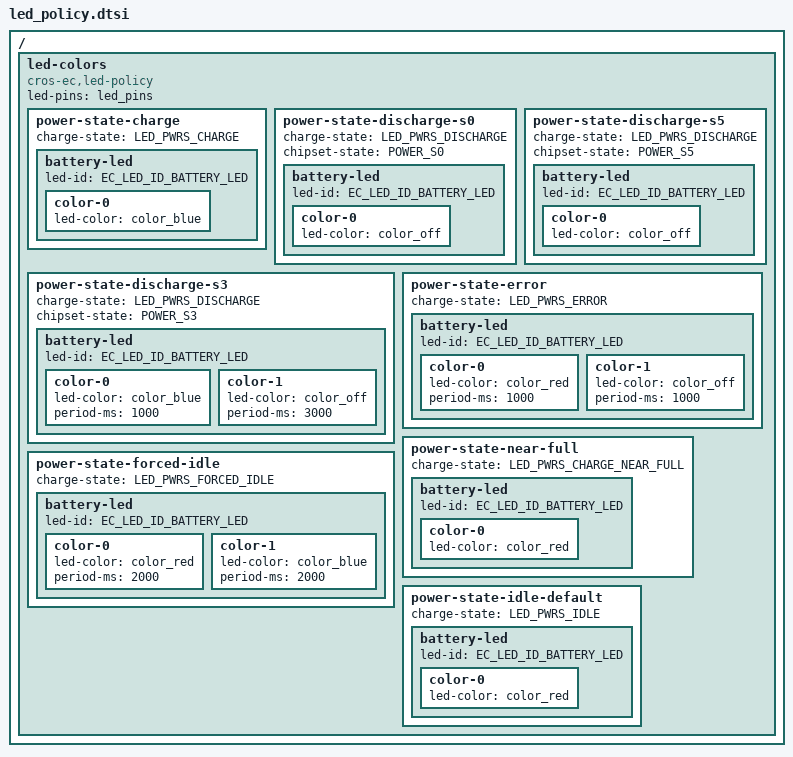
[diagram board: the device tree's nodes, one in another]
/* Copyright 2022 The ChromiumOS Authors
 * Use of this source code is governed by a BSD-style license that can be
 * found in the LICENSE file.
 */

/ {
	led-colors {
		compatible = "cros-ec,led-policy";
		led-pins = <&led_pins>;

		power-state-charge {
			charge-state = "LED_PWRS_CHARGE";

			battery-led {
				led-id = "EC_LED_ID_BATTERY_LED";
				color-0 {
					led-color = <&color_blue>;
				};
			};
		};

		power-state-discharge-s0 {
			charge-state = "LED_PWRS_DISCHARGE";
			chipset-state = "POWER_S0";

			battery-led {
				led-id = "EC_LED_ID_BATTERY_LED";
				color-0 {
					led-color = <&color_off>;
				};
			};
		};

		power-state-discharge-s3 {
			charge-state = "LED_PWRS_DISCHARGE";
			chipset-state = "POWER_S3";

			battery-led {
				led-id = "EC_LED_ID_BATTERY_LED";
				/* Blue 1 sec, off 3 sec */
				color-0 {
					led-color = <&color_blue>;
					period-ms = <1000>;
				};
				color-1 {
					led-color = <&color_off>;
					period-ms = <3000>;
				};
			};
		};

		power-state-discharge-s5 {
			charge-state = "LED_PWRS_DISCHARGE";
			chipset-state = "POWER_S5";

			battery-led {
				led-id = "EC_LED_ID_BATTERY_LED";
				color-0 {
					led-color = <&color_off>;
				};
			};
		};

		power-state-error {
			charge-state = "LED_PWRS_ERROR";

			battery-led {
				led-id = "EC_LED_ID_BATTERY_LED";
				/* Red 1 sec, off 1 sec */
				color-0 {
					led-color = <&color_red>;
					period-ms = <1000>;
				};
				color-1 {
					led-color = <&color_off>;
					period-ms = <1000>;
				};
			};
		};

		power-state-near-full {
			charge-state = "LED_PWRS_CHARGE_NEAR_FULL";

			battery-led {
				led-id = "EC_LED_ID_BATTERY_LED";
				color-0 {
					led-color = <&color_red>;
				};
			};
		};

		power-state-forced-idle {
			charge-state = "LED_PWRS_FORCED_IDLE";

			battery-led {
				led-id = "EC_LED_ID_BATTERY_LED";
				/* Red 2 sec, Blue 2 sec */
				color-0 {
					led-color = <&color_red>;
					period-ms = <2000>;
				};
				color-1 {
					led-color = <&color_blue>;
					period-ms = <2000>;
				};
			};
		};

		power-state-idle-default {
			charge-state = "LED_PWRS_IDLE";

			battery-led {
				led-id = "EC_LED_ID_BATTERY_LED";
				color-0 {
					led-color = <&color_red>;
				};
			};
		};
	};
};
